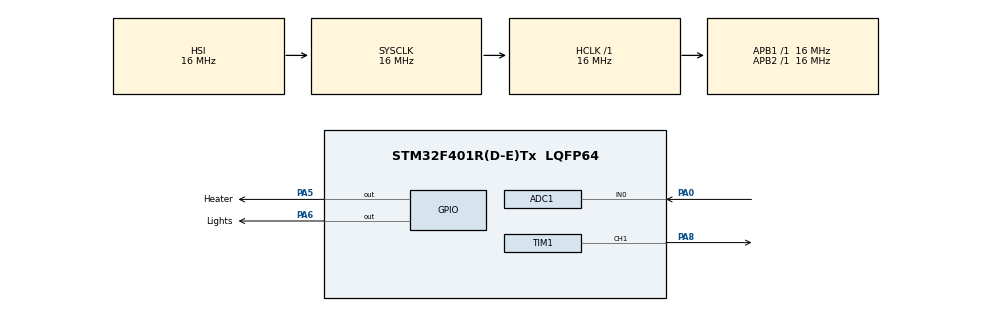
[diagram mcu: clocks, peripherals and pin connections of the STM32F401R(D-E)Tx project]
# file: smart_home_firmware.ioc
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ADC1.Channel-0\#ChannelRegularConversion=ADC_CHANNEL_0
ADC1.NbrOfConversionFlag=1
ADC1.Rank-0\#ChannelRegularConversion=1
ADC1.SamplingTime-0\#ChannelRegularConversion=ADC_SAMPLETIME_3CYCLES
ADC1.master=1
Mcu.Family=STM32F4
Mcu.Name=STM32F401R(D-E)Tx
Mcu.Package=LQFP64
NVIC.PriorityGroup=NVIC_PRIORITYGROUP_4
PA0-WKUP.Signal=ADCx_IN0
PA5.GPIO_Label=Heater
PA5.Signal=GPIO_Output
PA6.GPIO_Label=Lights
PA6.Signal=GPIO_Output
PA8.Signal=S_TIM1_CH1
ProjectManager.HeapSize=0x200
ProjectManager.StackSize=0x400
ProjectManager.TargetToolchain=CMake
RCC.AHBFreq_Value=16000000
RCC.APB1Freq_Value=16000000
RCC.APB2Freq_Value=16000000
RCC.CortexFreq_Value=16000000
RCC.HSE_VALUE=25000000
RCC.HSI_VALUE=16000000
RCC.LSE_VALUE=32768
RCC.SYSCLKFreq_VALUE=16000000
RCC.VCOOutputFreq_Value=192000000
SH.ADCx_IN0.0=ADC1_IN0,IN0
SH.S_TIM1_CH1.0=TIM1_CH1,PWM Generation1 CH1
TIM1.Channel-PWM\ Generation1\ CH1=TIM_CHANNEL_1
board=custom

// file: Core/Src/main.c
/* USER CODE BEGIN Header */
/**
  ******************************************************************************
  * @file           : main.c
  * @brief          : Main program body
  ******************************************************************************
  * @attention
  *
  * Copyright (c) 2026 STMicroelectronics.
  * All rights reserved.
  *
  * This software is licensed under terms that can be found in the LICENSE file
  * in the root directory of this software component.
  * If no LICENSE file comes with this software, it is provided AS-IS.
  *
  ******************************************************************************
  */
/* USER CODE END Header */
#include "main.h"
#include "adc.h"
#include "tim.h"
#include "gpio.h"

/* USER CODE BEGIN PV */
uint32_t raw_light_value = 0;
/* USER CODE END PV */

void SystemClock_Config(void);

int main(void)
{

  /* MCU Configuration--------------------------------------------------------*/

  /* Reset of all peripherals, Initializes the Flash interface and the Systick. */
  HAL_Init();

  /* Configure the system clock */
  SystemClock_Config();

  /* Initialize all configured peripherals */
  MX_GPIO_Init();
  MX_ADC1_Init();
  MX_TIM1_Init();

  /* Infinite loop */
  /* USER CODE BEGIN WHILE */
  while (1)
  {
    // 1. Start the ADC conversion on PA0
    HAL_ADC_Start(&hadc1);

    // 2. Poll for conversion complete (timeout = 10ms)
    if (HAL_ADC_PollForConversion(&hadc1, 10) == HAL_OK)
    {
      // 3. Read the 12-bit ADC result (0 to 4095)
      raw_light_value = HAL_ADC_GetValue(&hadc1);
    }

    // 4. Stop the ADC until next reading loop
    HAL_ADC_Stop(&hadc1);

    // Simple Threshold Logic: If room is dark (< 2000), turn ON the yellow Light LED (PA6)
    if (raw_light_value < 2000)
    {
      HAL_GPIO_WritePin(GPIOA, GPIO_PIN_6, GPIO_PIN_SET);   // Turn ON Yellow LED
    }
    else
    {
      HAL_GPIO_WritePin(GPIOA, GPIO_PIN_6, GPIO_PIN_RESET); // Turn OFF Yellow LED
    }

    // Toggle the red HEATER LED (PA5) periodically to show system heartbeats
    HAL_GPIO_TogglePin(GPIOA, GPIO_PIN_5);

    HAL_Delay(500);
    /* USER CODE END WHILE */

  }
}

void SystemClock_Config(void)
{
  RCC_OscInitTypeDef RCC_OscInitStruct = {0};
  RCC_ClkInitTypeDef RCC_ClkInitStruct = {0};

  /** Configure the main internal regulator output voltage
  */
  __HAL_RCC_PWR_CLK_ENABLE();
  __HAL_PWR_VOLTAGESCALING_CONFIG(PWR_REGULATOR_VOLTAGE_SCALE2);

  /** Initializes the RCC Oscillators according to the specified parameters
  * in the RCC_OscInitTypeDef structure.
  */
  RCC_OscInitStruct.OscillatorType = RCC_OSCILLATORTYPE_HSI;
  RCC_OscInitStruct.HSIState = RCC_HSI_ON;
  RCC_OscInitStruct.HSICalibrationValue = RCC_HSICALIBRATION_DEFAULT;
  RCC_OscInitStruct.PLL.PLLState = RCC_PLL_NONE;
  if (HAL_RCC_OscConfig(&RCC_OscInitStruct) != HAL_OK)
  {
    Error_Handler();
  }

  /** Initializes the CPU, AHB and APB buses clocks
  */
  RCC_ClkInitStruct.ClockType = RCC_CLOCKTYPE_HCLK|RCC_CLOCKTYPE_SYSCLK
                              |RCC_CLOCKTYPE_PCLK1|RCC_CLOCKTYPE_PCLK2;
  RCC_ClkInitStruct.SYSCLKSource = RCC_SYSCLKSOURCE_HSI;
  RCC_ClkInitStruct.AHBCLKDivider = RCC_SYSCLK_DIV1;
  RCC_ClkInitStruct.APB1CLKDivider = RCC_HCLK_DIV1;
  RCC_ClkInitStruct.APB2CLKDivider = RCC_HCLK_DIV1;

  if (HAL_RCC_ClockConfig(&RCC_ClkInitStruct, FLASH_LATENCY_0) != HAL_OK)
  {
    Error_Handler();
  }
}

void Error_Handler(void)
{
  __disable_irq();
  while (1)
  {
  }
}
